VERSION ""

NS_ :

BS_:

BU_: Tester RearECU MyECU

BO_ 17 VCUHV_Receive: 5 RearECU
 SG_ read_BmsBatteryTotal_Current : 32|1@1+ (1,0) [0|1] ""  MyECU
 SG_ read_DcdcWorking_Status : 24|1@1+ (1,0) [0|1] ""  MyECU
 SG_ read_BmsMainNegativeRelayClosed : 23|1@1+ (1,0) [0|1] ""  MyECU
 SG_ read_BmsRelayOff_Request : 22|1@1+ (1,0) [0|1] ""  MyECU
 SG_ read_BmsBattery_SocValue : 16|6@1+ (1,0) [0|100] ""  MyECU
 SG_ read_KeyONSwitch_Signal : 14|2@1+ (1,0) [0|1] ""  MyECU
 SG_ read_McuWorking_Status : 13|1@1+ (1,0) [0|1] ""  MyECU
 SG_ read_PduMainRelay_Status : 12|1@1+ (1,0) [0|1] ""  MyECU
 SG_ read_PduMainPrechargeRelay : 11|1@1+ (1,0) [0|1] ""  MyECU
 SG_ read_VehicleSpeed_Kph : 33|7@1+ (1,0) [0|100] ""  MyECU
 SG_ read_BrakePedal_Status : 9|1@1+ (1,0) [0|100] ""  MyECU
 SG_ read_ActualGear_Status : 8|1@1+ (1,0) [0|1] ""  MyECU
 SG_ read_AcceleratorPedal_Opening : 25|7@1+ (1,0) [0|100] ""  MyECU
 SG_ read_KeyStartSwitch_Signal : 6|1@1+ (1,0) [0|1] ""  MyECU
 SG_ read_FastChargePlug_Status : 5|1@1+ (1,0) [0|1] ""  MyECU
 SG_ read_SlowChargePlug_Status : 4|1@1+ (1,0) [0|1] ""  MyECU
 SG_ read_KeyOnSwitch_Signal : 3|1@1+ (1,0) [0|1] "" Vector__XXX
 SG_ read_BmsMainNegativeRelay_Status : 2|1@1+ (1,0) [0|1] ""  MyECU
 SG_ read_VehicleFaultLevel : 1|1@1+ (1,0) [0|100] ""  MyECU
 SG_ read_SelfCheck_Status : 0|1@1+ (1,0) [0|1] ""  MyECU

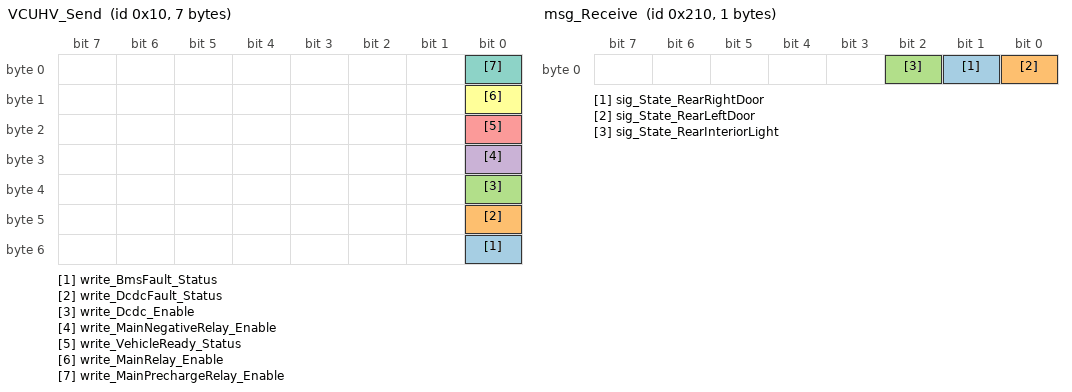
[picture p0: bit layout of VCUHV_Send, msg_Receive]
BO_ 16 VCUHV_Send: 7 MyECU
 SG_ write_BmsFault_Status : 48|1@1+ (1,0) [0|100] ""  RearECU
 SG_ write_DcdcFault_Status : 40|1@1+ (1,0) [0|100] "" Vector__XXX
 SG_ write_Dcdc_Enable : 32|1@1+ (1,0) [0|100] "" Vector__XXX
 SG_ write_MainNegativeRelay_Enable : 24|1@1+ (1,0) [0|1] ""  RearECU
 SG_ write_VehicleReady_Status : 16|1@1+ (1,0) [0|100] ""  RearECU
 SG_ write_MainRelay_Enable : 8|1@1+ (1,0) [0|100] ""  RearECU
 SG_ write_MainPrechargeRelay_Enable : 0|1@1+ (1,0) [0|100] ""  RearECU

BO_ 1297 msg_MyECU_Lamp: 8 MyECU
 SG_ sig_LampCnt : 7|8@0+ (1,0) [0|255] ""  RearECU

BO_ 1025 msg_nm_RearECU: 8 RearECU
 SG_ sig_nm_RearECU : 0|64@1+ (1,0) [0|1.8446744074E+019] ""  MyECU

BO_ 1024 msg_nm_MyECU: 8 MyECU
 SG_ sig_nm_MyECU : 0|64@1+ (1,0) [0|1.8446744074E+019] ""  RearECU

BO_ 1554 msg_diag_Response_MyECU: 8 MyECU
 SG_ sig_DiagResponseMyECU : 0|64@1+ (1,0) [0|1.8446744074E+019] ""  Tester

BO_ 1552 msg_diag_Request_MyECU: 8 Tester
 SG_ sig_DiagRequestMyECU : 0|64@1+ (1,0) [0|1.8446744074E+019] ""  MyECU

BO_ 1556 msg_diag_RequestGlobal: 8 Tester
 SG_ sig_DiagRequestGlobal : 0|64@1+ (1,0) [0|1.8446744074E+019] ""  MyECU

BO_ 512 msg_Transmit: 1 MyECU
 SG_ sig_RearInteriorLight : 0|1@1+ (1,0) [0|1] ""  RearECU

BO_ 528 msg_Receive: 1 RearECU
 SG_ sig_State_RearRightDoor : 1|1@1+ (1,0) [0|1] ""  MyECU
 SG_ sig_State_RearLeftDoor : 0|1@1+ (1,0) [0|1] ""  MyECU
 SG_ sig_State_RearInteriorLight : 2|1@1+ (1,0) [0|1] ""  MyECU

BA_DEF_ BO_  "GenMsgCycleTime" INT 0 0;
BA_DEF_ BO_  "GenMsgSendType" ENUM  "cyclicX","spontanX","cyclicIfActiveX","spontanWithDelay","cyclicAndSpontanX","cyclicAndSpontanWithDelay","spontanWithRepetition","cyclicIfActiveAndSpontanWD","cyclicIfActiveFast","cyclicWithRepeatOnDemand";
BA_DEF_ SG_  "GenSigCycleTimeActive" INT 0 0;
BA_DEF_ SG_  "GenSigCycleTime" INT 0 0;
BA_DEF_ SG_  "GenSigSendType" ENUM  "cyclicX","spontanX","cyclicIfActiveX","spontanWithDelay","cyclicAndSpontanX","cyclicAndSpontanWithDelay","spontanWithRepetition","cyclicIfActiveAndSpontanWD","cyclicIfActiveFast","cyclicWithRepeatOnDemand","none","NotUsed","NotUsed";
BA_DEF_  "Baudrate" INT 0 1000000;
BA_DEF_  "BusType" STRING ;
BA_DEF_  "NmType" STRING ;
BA_DEF_  "Manufacturer" STRING ;
BA_DEF_  "NmAsrWaitBusSleepTime" INT 0 65535;
BA_DEF_  "NmAsrTimeoutTime" INT 0 65535;
BA_DEF_  "NmAsrRepeatMessageTime" INT 0 65535;
BA_DEF_ BU_  "NmAsrNodeIdentifier" INT 0 255;
BA_DEF_ BU_  "NmAsrNode" ENUM  "no","yes";
BA_DEF_  "NmAsrMessageCount" INT 0 256;
BA_DEF_ BO_  "NmAsrMessage" ENUM  "no","yes";
BA_DEF_ BU_  "NmAsrCanMsgReducedTime" INT 0 65535;
BA_DEF_  "NmAsrCanMsgCycleTime" INT 0 65535;
BA_DEF_  "NmAsrBaseAddress" HEX 0 65535;
BA_DEF_ BU_  "ILUsed" ENUM  "no","yes";
BA_DEF_ BO_  "GenMsgILSupport" ENUM  "no","yes";
BA_DEF_ BO_  "DiagState" ENUM  "No","Yes";
BA_DEF_ BO_  "DiagResponse" ENUM  "No","Yes";
BA_DEF_ BO_  "DiagRequest" ENUM  "No","Yes";
BA_DEF_DEF_  "GenMsgCycleTime" 0;
BA_DEF_DEF_  "GenMsgSendType" "cyclicX";
BA_DEF_DEF_  "GenSigCycleTimeActive" 0;
BA_DEF_DEF_  "GenSigCycleTime" 0;
BA_DEF_DEF_  "GenSigSendType" "cyclicX";
BA_DEF_DEF_  "Baudrate" 500000;
BA_DEF_DEF_  "BusType" "";
BA_DEF_DEF_  "NmType" "";
BA_DEF_DEF_  "Manufacturer" "Vector";
BA_DEF_DEF_  "NmAsrWaitBusSleepTime" 750;
BA_DEF_DEF_  "NmAsrTimeoutTime" 1000;
BA_DEF_DEF_  "NmAsrRepeatMessageTime" 400;
BA_DEF_DEF_  "NmAsrNodeIdentifier" 0;
BA_DEF_DEF_  "NmAsrNode" "yes";
BA_DEF_DEF_  "NmAsrMessageCount" 64;
BA_DEF_DEF_  "NmAsrMessage" "no";
BA_DEF_DEF_  "NmAsrCanMsgReducedTime" 50;
BA_DEF_DEF_  "NmAsrCanMsgCycleTime" 100;
BA_DEF_DEF_  "NmAsrBaseAddress" 1024;
BA_DEF_DEF_  "ILUsed" "yes";
BA_DEF_DEF_  "GenMsgILSupport" "yes";
BA_DEF_DEF_  "DiagState" "No";
BA_DEF_DEF_  "DiagResponse" "No";
BA_DEF_DEF_  "DiagRequest" "No";
BA_ "NmType" "NmAsr";
BA_ "BusType" "CAN";
BA_ "Baudrate" 0;
BA_ "NmAsrNodeIdentifier" BU_ RearECU 1;
BA_ "GenMsgCycleTime" BO_ 1297 100;
BA_ "GenMsgILSupport" BO_ 1025 0;
BA_ "NmAsrMessage" BO_ 1025 1;
BA_ "GenMsgCycleTime" BO_ 1025 100;
BA_ "GenMsgILSupport" BO_ 1024 0;
BA_ "NmAsrMessage" BO_ 1024 1;
BA_ "GenMsgCycleTime" BO_ 1024 100;
BA_ "DiagResponse" BO_ 1554 1;
BA_ "GenMsgCycleTime" BO_ 1554 100;
BA_ "DiagRequest" BO_ 1552 1;
BA_ "GenMsgCycleTime" BO_ 1552 100;
BA_ "DiagState" BO_ 1556 1;
BA_ "GenMsgCycleTime" BO_ 1556 100;
BA_ "GenMsgCycleTime" BO_ 512 100;
BA_ "GenMsgCycleTime" BO_ 528 100;
BA_ "GenSigCycleTime" SG_ 17 read_BmsBatteryTotal_Current 10;
BA_ "GenSigCycleTime" SG_ 17 read_DcdcWorking_Status 10;
BA_ "GenSigCycleTime" SG_ 17 read_BmsMainNegativeRelayClosed 10;
BA_ "GenSigCycleTime" SG_ 17 read_BmsRelayOff_Request 10;
BA_ "GenSigCycleTime" SG_ 17 read_BmsBattery_SocValue 10;
BA_ "GenSigCycleTime" SG_ 17 read_KeyONSwitch_Signal 10;
BA_ "GenSigCycleTime" SG_ 17 read_McuWorking_Status 10;
BA_ "GenSigCycleTime" SG_ 17 read_PduMainRelay_Status 10;
BA_ "GenSigCycleTime" SG_ 17 read_PduMainPrechargeRelay 10;
BA_ "GenSigCycleTime" SG_ 17 read_VehicleSpeed_Kph 10;
BA_ "GenSigCycleTime" SG_ 17 read_BrakePedal_Status 10;
BA_ "GenSigCycleTime" SG_ 17 read_ActualGear_Status 10;
BA_ "GenSigCycleTime" SG_ 17 read_AcceleratorPedal_Opening 10;
BA_ "GenSigCycleTime" SG_ 17 read_KeyStartSwitch_Signal 10;
BA_ "GenSigCycleTime" SG_ 17 read_FastChargePlug_Status 10;
BA_ "GenSigCycleTime" SG_ 17 read_SlowChargePlug_Status 10;
BA_ "GenSigCycleTime" SG_ 17 read_KeyOnSwitch_Signal 10;
BA_ "GenSigCycleTime" SG_ 17 read_BmsMainNegativeRelay_Status 10;
BA_ "GenSigCycleTime" SG_ 17 read_VehicleFaultLevel 10;
BA_ "GenSigCycleTime" SG_ 17 read_SelfCheck_Status 10;
BA_ "GenSigCycleTime" SG_ 16 write_BmsFault_Status 10;
BA_ "GenSigCycleTime" SG_ 16 write_DcdcFault_Status 10;
BA_ "GenSigCycleTime" SG_ 16 write_Dcdc_Enable 10;
BA_ "GenSigCycleTime" SG_ 16 write_MainNegativeRelay_Enable 10;
BA_ "GenSigCycleTime" SG_ 16 write_VehicleReady_Status 10;
BA_ "GenSigCycleTime" SG_ 16 write_MainRelay_Enable 10;
BA_ "GenSigCycleTime" SG_ 16 write_MainPrechargeRelay_Enable 10;
BA_ "GenSigCycleTime" SG_ 1025 sig_nm_RearECU 100;
BA_ "GenSigCycleTimeActive" SG_ 1025 sig_nm_RearECU 100;
BA_ "GenSigCycleTime" SG_ 1024 sig_nm_MyECU 100;
BA_ "GenSigCycleTimeActive" SG_ 1024 sig_nm_MyECU 100;
BA_ "GenSigCycleTime" SG_ 1554 sig_DiagResponseMyECU 100;
BA_ "GenSigCycleTimeActive" SG_ 1554 sig_DiagResponseMyECU 100;
BA_ "GenSigCycleTime" SG_ 1552 sig_DiagRequestMyECU 100;
BA_ "GenSigCycleTimeActive" SG_ 1552 sig_DiagRequestMyECU 100;
BA_ "GenSigCycleTime" SG_ 1556 sig_DiagRequestGlobal 100;
BA_ "GenSigCycleTimeActive" SG_ 1556 sig_DiagRequestGlobal 100;
BA_ "GenSigCycleTime" SG_ 512 sig_RearInteriorLight 100;
BA_ "GenSigCycleTimeActive" SG_ 512 sig_RearInteriorLight 100;
BA_ "GenSigCycleTime" SG_ 528 sig_State_RearRightDoor 100;
BA_ "GenSigCycleTimeActive" SG_ 528 sig_State_RearRightDoor 100;
BA_ "GenSigCycleTime" SG_ 528 sig_State_RearLeftDoor 100;
BA_ "GenSigCycleTimeActive" SG_ 528 sig_State_RearLeftDoor 100;
BA_ "GenSigCycleTime" SG_ 528 sig_State_RearInteriorLight 100;
BA_ "GenSigCycleTimeActive" SG_ 528 sig_State_RearInteriorLight 100;
